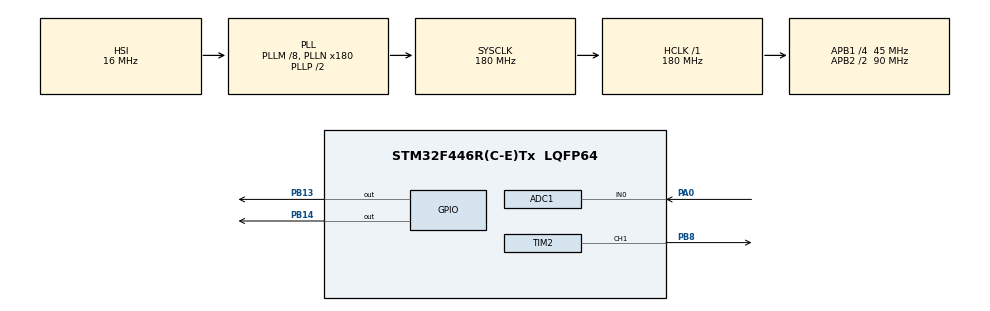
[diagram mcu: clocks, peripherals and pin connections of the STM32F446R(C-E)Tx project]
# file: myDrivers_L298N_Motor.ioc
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ADC1.Channel-0\#ChannelRegularConversion=ADC_CHANNEL_0
ADC1.NbrOfConversionFlag=1
ADC1.Rank-0\#ChannelRegularConversion=1
ADC1.SamplingTime-0\#ChannelRegularConversion=ADC_SAMPLETIME_3CYCLES
ADC1.master=1
Mcu.Family=STM32F4
Mcu.Name=STM32F446R(C-E)Tx
Mcu.Package=LQFP64
NVIC.PriorityGroup=NVIC_PRIORITYGROUP_4
PA0-WKUP.Signal=ADCx_IN0
PA13.Mode=Serial_Wire
PA13.Signal=SYS_JTMS-SWDIO
PA14.Mode=Serial_Wire
PA14.Signal=SYS_JTCK-SWCLK
PB13.GPIO_Speed=GPIO_SPEED_FREQ_VERY_HIGH
PB13.Signal=GPIO_Output
PB14.GPIO_Speed=GPIO_SPEED_FREQ_VERY_HIGH
PB14.Signal=GPIO_Output
PB8.Signal=S_TIM2_CH1_ETR
PC14-OSC32_IN.Mode=LSE-External-Oscillator
PC14-OSC32_IN.Signal=RCC_OSC32_IN
PC15-OSC32_OUT.Mode=LSE-External-Oscillator
PC15-OSC32_OUT.Signal=RCC_OSC32_OUT
PH0-OSC_IN.Mode=HSE-External-Oscillator
PH0-OSC_IN.Signal=RCC_OSC_IN
PH1-OSC_OUT.Mode=HSE-External-Oscillator
PH1-OSC_OUT.Signal=RCC_OSC_OUT
ProjectManager.HeapSize=0x200
ProjectManager.StackSize=0x400
ProjectManager.TargetToolchain=STM32CubeIDE
RCC.AHBFreq_Value=180000000
RCC.APB1CLKDivider=RCC_HCLK_DIV4
RCC.APB1Freq_Value=45000000
RCC.APB1TimFreq_Value=90000000
RCC.APB2CLKDivider=RCC_HCLK_DIV2
RCC.APB2Freq_Value=90000000
RCC.APB2TimFreq_Value=180000000
RCC.CortexFreq_Value=180000000
RCC.HCLKFreq_Value=180000000
RCC.PLLM=8
RCC.PLLN=180
RCC.SYSCLKFreq_VALUE=180000000
RCC.SYSCLKSource=RCC_SYSCLKSOURCE_PLLCLK
RCC.USBFreq_Value=180000000
RCC.VCOOutputFreq_Value=360000000
SH.ADCx_IN0.0=ADC1_IN0,IN0
SH.S_TIM2_CH1_ETR.0=TIM2_CH1,PWM Generation1 CH1
TIM2.Channel-PWM\ Generation1\ CH1=TIM_CHANNEL_1
TIM2.Period=1999
TIM2.Prescaler=8
board=custom

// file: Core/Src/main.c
/* USER CODE BEGIN Header */
/**
  ******************************************************************************
  * @file           : main.c
  * @brief          : Main program body
  ******************************************************************************
  * @attention
  *
  * Copyright (c) 2025 STMicroelectronics.
  * All rights reserved.
  *
  * This software is licensed under terms that can be found in the LICENSE file
  * in the root directory of this software component.
  * If no LICENSE file comes with this software, it is provided AS-IS.
  *
  ******************************************************************************
  */
/* USER CODE END Header */
#include "main.h"

/* USER CODE BEGIN Includes */
#include "POT.h"
#include "L298N.h"
/* USER CODE END Includes */

ADC_HandleTypeDef hadc1;

TIM_HandleTypeDef htim2;

/* USER CODE BEGIN PV */
extern L298N_Direction_t motorDirection;
uint32_t potValue;
uint32_t dutyValue;
/* USER CODE END PV */

void SystemClock_Config(void);
static void MX_GPIO_Init(void);
static void MX_TIM2_Init(void);
static void MX_ADC1_Init(void);

int main(void)
{

  /* MCU Configuration--------------------------------------------------------*/

  /* Reset of all peripherals, Initializes the Flash interface and the Systick. */
  HAL_Init();

  /* Configure the system clock */
  SystemClock_Config();

  /* Initialize all configured peripherals */
  MX_GPIO_Init();
  MX_TIM2_Init();
  MX_ADC1_Init();
  /* USER CODE BEGIN 2 */
  L298N_init(&htim2);
  /* USER CODE END 2 */

  /* Infinite loop */
  while (1)
  {

    /* USER CODE BEGIN 3 */
	  potValue = POT_read(&hadc1);
	  dutyValue = POT_map(potValue, 0, 4095, 0, 100);
	  motorDirection = LEFT;
	  L298N_setDirection(motorDirection);
	  L298N_setPWM(&htim2,TIM_CHANNEL_1, dutyValue);
  }
  /* USER CODE END 3 */
}

void SystemClock_Config(void)
{
  RCC_OscInitTypeDef RCC_OscInitStruct = {0};
  RCC_ClkInitTypeDef RCC_ClkInitStruct = {0};

  /** Configure the main internal regulator output voltage
  */
  __HAL_RCC_PWR_CLK_ENABLE();
  __HAL_PWR_VOLTAGESCALING_CONFIG(PWR_REGULATOR_VOLTAGE_SCALE1);

  /** Initializes the RCC Oscillators according to the specified parameters
  * in the RCC_OscInitTypeDef structure.
  */
  RCC_OscInitStruct.OscillatorType = RCC_OSCILLATORTYPE_HSI;
  RCC_OscInitStruct.HSIState = RCC_HSI_ON;
  RCC_OscInitStruct.HSICalibrationValue = RCC_HSICALIBRATION_DEFAULT;
  RCC_OscInitStruct.PLL.PLLState = RCC_PLL_ON;
  RCC_OscInitStruct.PLL.PLLSource = RCC_PLLSOURCE_HSI;
  RCC_OscInitStruct.PLL.PLLM = 8;
  RCC_OscInitStruct.PLL.PLLN = 180;
  RCC_OscInitStruct.PLL.PLLP = RCC_PLLP_DIV2;
  RCC_OscInitStruct.PLL.PLLQ = 2;
  RCC_OscInitStruct.PLL.PLLR = 2;
  if (HAL_RCC_OscConfig(&RCC_OscInitStruct) != HAL_OK)
  {
    Error_Handler();
  }

  /** Activate the Over-Drive mode
  */
  if (HAL_PWREx_EnableOverDrive() != HAL_OK)
  {
    Error_Handler();
  }

  /** Initializes the CPU, AHB and APB buses clocks
  */
  RCC_ClkInitStruct.ClockType = RCC_CLOCKTYPE_HCLK|RCC_CLOCKTYPE_SYSCLK
                              |RCC_CLOCKTYPE_PCLK1|RCC_CLOCKTYPE_PCLK2;
  RCC_ClkInitStruct.SYSCLKSource = RCC_SYSCLKSOURCE_PLLCLK;
  RCC_ClkInitStruct.AHBCLKDivider = RCC_SYSCLK_DIV1;
  RCC_ClkInitStruct.APB1CLKDivider = RCC_HCLK_DIV4;
  RCC_ClkInitStruct.APB2CLKDivider = RCC_HCLK_DIV2;

  if (HAL_RCC_ClockConfig(&RCC_ClkInitStruct, FLASH_LATENCY_5) != HAL_OK)
  {
    Error_Handler();
  }
}

static void MX_ADC1_Init(void)
{

  ADC_ChannelConfTypeDef sConfig = {0};

  /** Configure the global features of the ADC (Clock, Resolution, Data Alignment and number of conversion)
  */
  hadc1.Instance = ADC1;
  hadc1.Init.ClockPrescaler = ADC_CLOCK_SYNC_PCLK_DIV4;
  hadc1.Init.Resolution = ADC_RESOLUTION_12B;
  hadc1.Init.ScanConvMode = DISABLE;
  hadc1.Init.ContinuousConvMode = DISABLE;
  hadc1.Init.DiscontinuousConvMode = DISABLE;
  hadc1.Init.ExternalTrigConvEdge = ADC_EXTERNALTRIGCONVEDGE_NONE;
  hadc1.Init.ExternalTrigConv = ADC_SOFTWARE_START;
  hadc1.Init.DataAlign = ADC_DATAALIGN_RIGHT;
  hadc1.Init.NbrOfConversion = 1;
  hadc1.Init.DMAContinuousRequests = DISABLE;
  hadc1.Init.EOCSelection = ADC_EOC_SINGLE_CONV;
  if (HAL_ADC_Init(&hadc1) != HAL_OK)
  {
    Error_Handler();
  }

  /** Configure for the selected ADC regular channel its corresponding rank in the sequencer and its sample time.
  */
  sConfig.Channel = ADC_CHANNEL_0;
  sConfig.Rank = 1;
  sConfig.SamplingTime = ADC_SAMPLETIME_3CYCLES;
  if (HAL_ADC_ConfigChannel(&hadc1, &sConfig) != HAL_OK)
  {
    Error_Handler();
  }

}

static void MX_TIM2_Init(void)
{

  TIM_MasterConfigTypeDef sMasterConfig = {0};
  TIM_OC_InitTypeDef sConfigOC = {0};

  htim2.Instance = TIM2;
  htim2.Init.Prescaler = 8;
  htim2.Init.CounterMode = TIM_COUNTERMODE_UP;
  htim2.Init.Period = 1999;
  htim2.Init.ClockDivision = TIM_CLOCKDIVISION_DIV1;
  htim2.Init.AutoReloadPreload = TIM_AUTORELOAD_PRELOAD_DISABLE;
  if (HAL_TIM_PWM_Init(&htim2) != HAL_OK)
  {
    Error_Handler();
  }
  sMasterConfig.MasterOutputTrigger = TIM_TRGO_RESET;
  sMasterConfig.MasterSlaveMode = TIM_MASTERSLAVEMODE_DISABLE;
  if (HAL_TIMEx_MasterConfigSynchronization(&htim2, &sMasterConfig) != HAL_OK)
  {
    Error_Handler();
  }
  sConfigOC.OCMode = TIM_OCMODE_PWM1;
  sConfigOC.Pulse = 0;
  sConfigOC.OCPolarity = TIM_OCPOLARITY_HIGH;
  sConfigOC.OCFastMode = TIM_OCFAST_DISABLE;
  if (HAL_TIM_PWM_ConfigChannel(&htim2, &sConfigOC, TIM_CHANNEL_1) != HAL_OK)
  {
    Error_Handler();
  }
  HAL_TIM_MspPostInit(&htim2);

}

static void MX_GPIO_Init(void)
{
  GPIO_InitTypeDef GPIO_InitStruct = {0};

  /* GPIO Ports Clock Enable */
  __HAL_RCC_GPIOC_CLK_ENABLE();
  __HAL_RCC_GPIOH_CLK_ENABLE();
  __HAL_RCC_GPIOA_CLK_ENABLE();
  __HAL_RCC_GPIOB_CLK_ENABLE();

  /*Configure GPIO pin Output Level */
  HAL_GPIO_WritePin(GPIOB, GPIO_PIN_13|GPIO_PIN_14, GPIO_PIN_RESET);

  /*Configure GPIO pins : PB13 PB14 */
  GPIO_InitStruct.Pin = GPIO_PIN_13|GPIO_PIN_14;
  GPIO_InitStruct.Mode = GPIO_MODE_OUTPUT_PP;
  GPIO_InitStruct.Pull = GPIO_NOPULL;
  GPIO_InitStruct.Speed = GPIO_SPEED_FREQ_VERY_HIGH;
  HAL_GPIO_Init(GPIOB, &GPIO_InitStruct);

}

void Error_Handler(void)
{
  __disable_irq();
  while (1)
  {
  }
}
